# rCSL_ecap_001 register map
Vendor: Texas Instruments
Peripheral module from a debugger description file (folder OMAPL138_C6748).
Registers are 32-bit, read-write, reset 0x0 unless marked. A register's access mark holds for its fields unless they carry their own. Offsets are as the file gives them; lines under a group give offsets from that group; [hi:lo] are bit positions; {n}, {i} and the like mark numbered series; 'fields as' and 'values as' point back to an identical list; <NAME> marks a mode.

## ECAP — Capture module used for timng of external events. Provides hi-res timebase, can take elapsed-time measurements.
0x00 TSCTR — Time-stamp counter
  [31:0] TSCTR — 32-bit counter; capture time-base
0x04 CTRPHS — Counter phase control
  [31:0] CTRPHS — Counter phase offset; shadows TSCTR
{0x4+4i} CAP{i} (i=1..4) — Capture-{i}
  [31:0] CAP{i} — Capture-{i} value
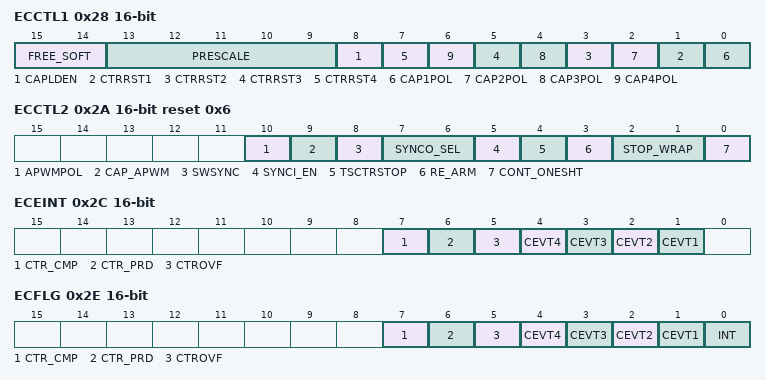
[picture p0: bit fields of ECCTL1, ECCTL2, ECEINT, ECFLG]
0x28 ECCTL1 16-bit — Capture control 1
  [15:14] FREE_SOFT — Capture-4 value
    0=STOP; 1=RUNUNTIL0; 2=RUNFREE; 3=RUNFREE
  [13:9] PRESCALE — Event filter prescale select
  [8] CAPLDEN — Enable loading of CAP1-4 on capture event
    0=DISABLE; 1=ENABLE
  [2n-1] CTRRST{n} (n=1..4) — Counter rest on cap event {n}
    0=NORESET; 1=RESET
  [2n-2] CAP{n}POL (n=1..4) — Capture event {n} polarity select
    0=RISINGEDGE; 1=FALLINGEDGE
0x2A ECCTL2 16-bit access not given reset 0x6 — Capture control 2
  [10] APWMPOL rw — APWM output polarity
    0=ACTIVEHIGH; 1=ACTIVELOW
  [9] CAP_APWM rw — CAP/APWM mode select
    0=CAPMODE; 1=APWMMODE
  [8] SWSYNC rw — Software-forced counter sync
    0=NOEFFECT; 1=TSCTRLOAD
  [7:6] SYNCO_SEL rw — Sync-out select
    0=SYNCIN; 1=CTREQUALPRD; 2=DISABLE; 3=DISABLE
  [5] SYNCI_EN rw — Counter sync-in select
    0=DISABLE; 1=ENABLE
  [4] TSCTRSTOP rw — Time stamp counter stop control
    0=STOPPED; 1=FREERUNNING
  [3] RE_ARM rw — One-shot re-arming control
    0=NOEFFECT; 1=ARMED
  [2:1] STOP_WRAP rw — STOP/WRAP value
    {v}=CAP{v+1} (v=0..3)
  [0] CONT_ONESHT rw — Continuous/one-shot mode control
    0=CONTINUOUS; 1=ONESHOT
0x2C ECEINT 16-bit access not given — Interrupt enable register
  [all] fields
    0=DISABLE; 1=ENABLE
  [7] CTR_CMP rw — Counter equal compare interrupt enable
  [6] CTR_PRD rw — Counter equal period interrupt enable
  [5] CTROVF rw — Counter overflow interrupt enable
  [n] CEVT{n} rw (n=1..4) — Capture event {n} interrupt enable
0x2E ECFLG 16-bit access not given — Interrupt flag register
  [all] fields
    0=NOINT; 1=INT
  [7] CTR_CMP rw — Counter equal compare status flag
  [6] CTR_PRD rw — Counter equal period status flag
  [5] CTROVF rw — Counter overflow status flag
  [n] CEVT{n} rw (n=1..4) — Capture event {n} status flag
  [0] INT rw — Global interrupt status flag
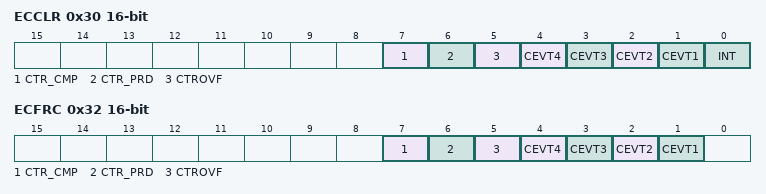
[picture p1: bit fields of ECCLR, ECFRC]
0x30 ECCLR 16-bit access not given — Interrupt clear register
  [all] fields
    0=NOEFFECT; 1=CLEAR
  [7] CTR_CMP rw — Counter equal compare status flag
  [6] CTR_PRD rw — Counter equal period status flag
  [5] CTROVF rw — Counter overflow status flag
  [n] CEVT{n} rw (n=1..4) — Capture event {n} status flag
  [0] INT rw — Global interrupt status flag
0x32 ECFRC 16-bit access not given — Interrupt forcing register
  [all] fields
    0=NOEFFECT; 1=FORCE
  [7] CTR_CMP rw — Force counter equal compare interrupt
  [6] CTR_PRD rw — Force counter equal period interrupt
  [5] CTROVF rw — Force counter overflow interrupt
  [n] CEVT{n} rw (n=1..4) — Force capture event {n} interrupt
0x5C REVID ro reset 0x44D22100 — Revision ID
